# ipro6s register map
Vendor: intelpro; Series: IPRO6S
CPU: ipro6s, little endian
Registers are 32-bit, read-write, reset 0x0 unless marked. A register's access mark holds for its fields unless they carry their own. Offsets are from the block's base; [hi:lo] are bit positions; lines under a group give offsets from that group; {n}, {i} and the like mark numbered series; 'fields as' and 'values as' point back to an identical list.

## GLB
Base 0x30000000
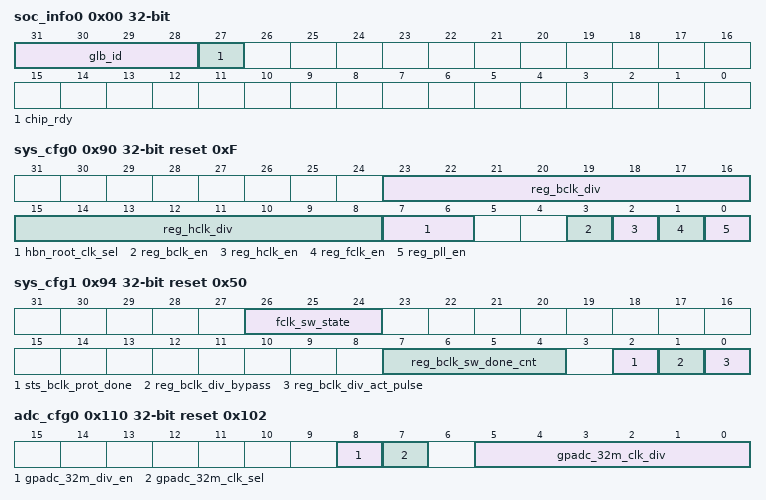
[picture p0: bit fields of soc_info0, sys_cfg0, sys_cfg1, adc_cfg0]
0x00 soc_info0 reset not defined
  [31:28] glb_id ro, [27] chip_rdy ro
0x50 core_cfg16 reset not defined
  [31:0] np_int_sta0 ro — NP interrupt status [31:0]
0x54 core_cfg17 reset not defined
  [31:0] np_int_sta1 ro — NP interrupt status [63:32]
0x58 core_cfg18
  [31:0] np_int_mask0
0x5C core_cfg19
  [31:0] np_int_mask1
0x60 core_cfg20
  [31:0] np_int_clr0 wo
0x64 core_cfg21
  [31:0] np_int_clr1 wo
0x90 sys_cfg0 reset 0xF (reset mask 0xFFFF0F)
  [23:16] reg_bclk_div — bclk divide from hclk
  [15:8] reg_hclk_div — hclk divide from root clock (clock source selected by hbn_root_clk_sel)
  [7:6] hbn_root_clk_sel ro — root clock selection from HBN (0: RC32M 1: XTAL 2/3: PLL others)
  [3] reg_bclk_en — bclk force on
  [2] reg_hclk_en — hclk force on
  [1] reg_fclk_en — fclk force on
  [0] reg_pll_en — pll clock enable for fclk
0x94 sys_cfg1 reset 0x50 (reset mask 0xF3)
  [26:24] fclk_sw_state ro
  [7:4] reg_bclk_sw_done_cnt — BCLK division protection done counter
  [2] sts_bclk_prot_done ro — clk protection done
  [1] reg_bclk_div_bypass — BCLK division protection bypass
  [0] reg_bclk_div_act_pulse wo — BCLK division protection activation
0xA0 bus_cfg0 reset 0xFFFFFFFF
  [31:0] rg_apb_pck_force — APB clock force on
0xF0 rtc_cfg0 reset not defined
0x110 adc_cfg0 reset 0x102
  [8] gpadc_32m_div_en — GPADC 32M Clock Dvider Enable
  [7] gpadc_32m_clk_sel — GPADC Clock Source Select. 0: audio_pll_clk, 1: xclk
  [5:0] gpadc_32m_clk_div — GPADC 32M Clock Divider (audio_pll_clk)/(N+1) , default : audio_pll_clk/3
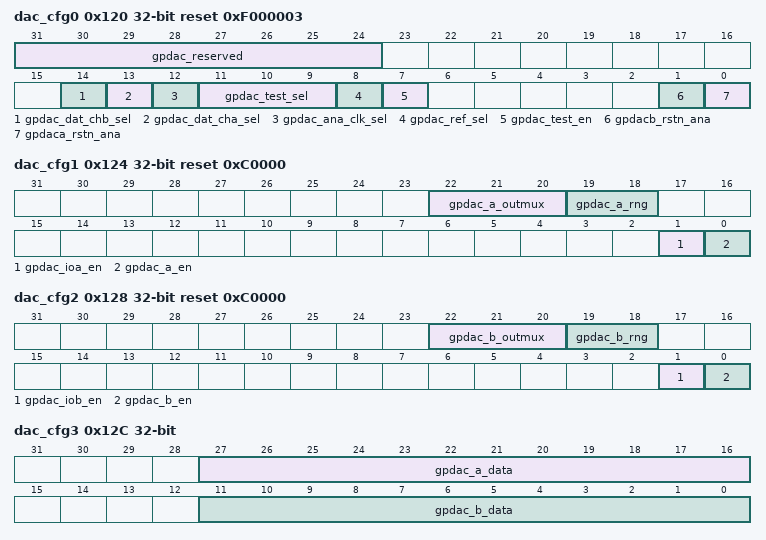
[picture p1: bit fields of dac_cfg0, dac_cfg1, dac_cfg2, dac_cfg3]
0x120 dac_cfg0 reset 0xF000003
  [31:24] gpdac_reserved
  [14] gpdac_dat_chb_sel — 0:data from gpip, 1:data from audio pwm
  [13] gpdac_dat_cha_sel — 0:data from gpip, 1:data from audio pwm
  [12] gpdac_ana_clk_sel — 0:clock from gpip, 1:clock from audio pwm
  [11:9] gpdac_test_sel — select test point 0~7
  [8] gpdac_ref_sel — Reference select 1'h0 Internal reference 1'h1 External reference
  [7] gpdac_test_en — Test enable 1'h0 analog test disabled (ATEST is set in Hi-Z state) 1'h1 analog test point enabled to ATEST
  [1] gpdacb_rstn_ana — Soft reset for DAC channel B, active low
  [0] gpdaca_rstn_ana — Soft reset for DAC channel A, active low
0x124 dac_cfg1 reset 0xC0000
  [22:20] gpdac_a_outmux
  [19:18] gpdac_a_rng — Output voltage range control with internal/external reference
  [1] gpdac_ioa_en — Channel A conversion output to pad enable 1'h0 Disable channel A conversion result to GPIO 1'h1 Enable channel A conversion result to GPIO
  [0] gpdac_a_en — Channel A enable/disable signal 1'h0 Disable channel A conversion. 1'h1 Enable channel A conversion
0x128 dac_cfg2 reset 0xC0000
  [22:20] gpdac_b_outmux
  [19:18] gpdac_b_rng
  [1] gpdac_iob_en — channel B conversion output to pad enable 1'h0 Disable channel B conversion result to GPIO 1'h1 Enable channel B conversion result to GPIO
  [0] gpdac_b_en — channel B enable/disable signal 1'h0 Disable channel B conversion. 1'h1 Enable channel B conversion
0x12C dac_cfg3
  [27:16] gpdac_a_data — Channel A Data input
  [11:0] gpdac_b_data — Channel B Data input
0x130 dma_cfg0 reset 0xFF000000
  [31:24] dma_clk_en — DMA Channel Clock Enable
0x134 dma_cfg1 reset not defined
0x138 dma_cfg2 reset not defined
0x140 ir_cfg0 reset not defined
0x144 ir_cfg1
  [11:8] ir_rx_gpio_sel — 0 : disable ir_rx select gpio 1~15 :select gpio 9 ~ 23 as ir_rx (GPIO need to set as SWGPIO mode)
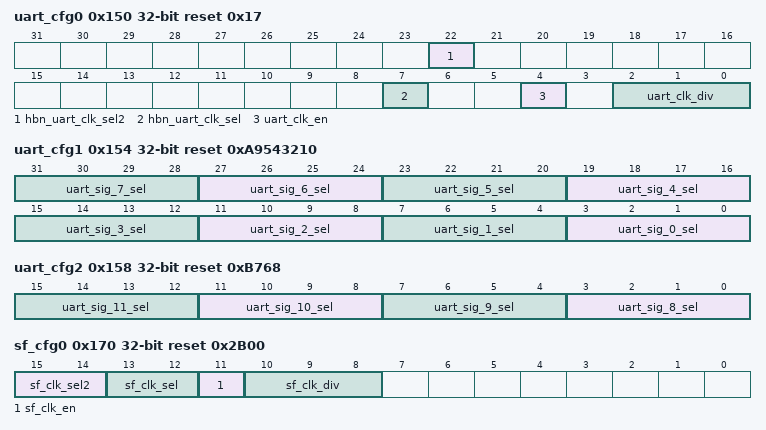
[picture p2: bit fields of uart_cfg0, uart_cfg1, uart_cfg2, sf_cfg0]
0x150 uart_cfg0 reset 0x17 (reset mask 0x17)
  [22] hbn_uart_clk_sel2 ro — UART clock selection2 from HBN (0 : result of hbn_uart_clk_sel (bclk or MUX 160MHz), 1: XCLK (XTAL or RC32M))
  [7] hbn_uart_clk_sel ro — UART clock selection from HBN (0:bclk 1:muxpll_160m_clk)
  [4] uart_clk_en — UART Clock Enable
  [2:0] uart_clk_div — UART Clock Divider (root clock or 160M)/(N+1) (clock source selected by hbn_uart_clk_sel)
0x154 uart_cfg1 reset 0xA9543210
  [4n+3:4n] uart_sig_{n}_sel (n=0..7) — UART Signal{n} Select : 0 : UART0_RTS 1 : UART0_CTS 2 : UART0_TXD 3 : UART0_RXD 4 : UART1_RTS 5 : UART1_CTS 6 : UART1_TXD 7 : UART1_RXD 8 : ~CAN_TXD 9 : x 10 : CAN_TXD 11 : CAN_RXD
0x158 uart_cfg2 reset 0xB768
  [4n-29:4n-32] uart_sig_{n}_sel (n=8..11) — UART Signal{n} Select
0x170 sf_cfg0 reset 0x2B00
  [15:14] sf_clk_sel2 — For sf_clk_sel=0 0/2: wifipll 120MHz 1: XTAL 2: aupll_div5 (98.3 or 90.3MHz) (for De-Spur)
  [13:12] sf_clk_sel — Flash Clock Select 0: clock from sf_clk_sel2 1: clock from muxpll_80m_clk (see 0x20000254 description) 2: bclk 3: wifipll 96MHz
  [11] sf_clk_en — Flash Clock Enable
  [10:8] sf_clk_div — Flash Clock Divider (Selected Flash Clock)/(N+1)
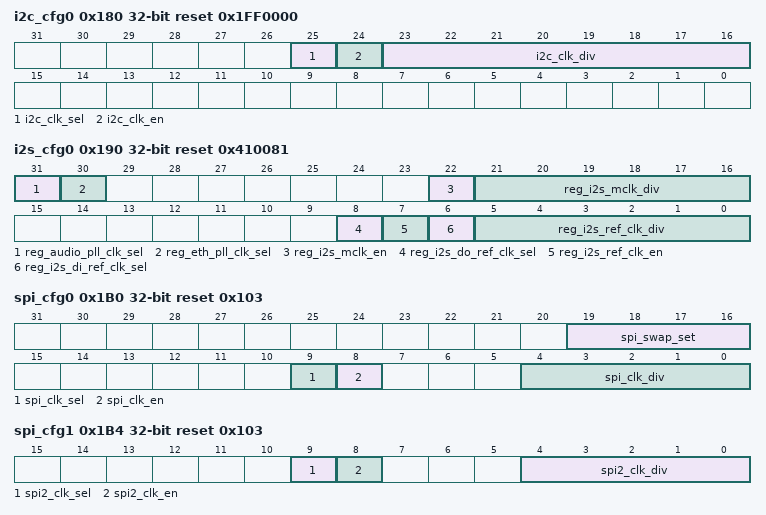
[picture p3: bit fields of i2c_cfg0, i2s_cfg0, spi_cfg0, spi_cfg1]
0x180 i2c_cfg0 reset 0x1FF0000
  [25] i2c_clk_sel — 0 : Bus Clcok to I2C Clock Divider 1 : XCLK clock to I2C Clock Divider
  [24] i2c_clk_en — I2C Master Clock Out Enable
  [23:16] i2c_clk_div — I2C Master Clock Out Divider (Freq_of_BCLK/(N+1))
0x190 i2s_cfg0 reset 0x410081
  [31] reg_audio_pll_clk_sel — 1:sscdiv_clk_out 0:wifipll_postdiv_outclk
  [30] reg_eth_pll_clk_sel — 1:sscdiv_clk_out 0:wifipll_postdiv_outclk
  [22] reg_i2s_mclk_en — Audio I2S Clock Enable
  [21:16] reg_i2s_mclk_div — Audio I2S Clock Divider (AUD_CLK/(N+1)), default AUD_CLK/2
  [8] reg_i2s_do_ref_clk_sel — Audio I2S Clock Output Enable 1 (1: Select i2s_ref_clk output, 0 : Select i2s_do output)
  [7] reg_i2s_ref_clk_en — Audio I2S Clock Enable
  [6] reg_i2s_di_ref_clk_sel — Audio I2S Clock Output Enable 0 (1: Select i2s_ref_clk output, 0: Select i2s_di input)
  [5:0] reg_i2s_ref_clk_div — Audio I2S Clock Divider (AUD_CLK/(N+1)), default AUD_CLK/2
0x1B0 spi_cfg0 reset 0x103
  [19:16] spi_swap_set — [0] SWAP UART GPIO SET0 (GPIO0~GPIO11) (1: spi_sig[0:11] -> spi_sig[6:11], spi_sig[0:5]) [1] SWAP UART GPIO SET0 (GPIO12~GPIO23) (1: spi_sig[0:11] -> spi_sig[6:11], spi_sig[0:5]) [2] SWAP UART GPIO SET0 (GPIO24~GPIO35) (1: spi_sig[0:11] -> spi_sig[6:11], spi_sig[0:5]) [3] SWAP UART GPIO SET0 (GPIO36~GPIO45) (1: spi_sig[0:11] -> spi_sig[6:11], spi_sig[0:5])
  [9] spi_clk_sel — 0 : MUXPLL_160M Hz to SPI Clock Divider (see 0x254h reg_top_muxpll_160m_sel) 1: XCLK (XTAL or RC32M) to SPI Clock Divider
  [8] spi_clk_en — SPI Clock Enable (Default : Enable)
  [4:0] spi_clk_div — SPI Clock Divider (BUS_CLK/(N+1)), default BUS_CLK/4
0x1B4 spi_cfg1 reset 0x103
  [9] spi2_clk_sel — 0 : MUXPLL_160M Hz to SPI Clock Divider (see 0x254h reg_top_muxpll_160m_sel) 1: XCLK (XTAL or RC32M) to SPI Clock Divider
  [8] spi2_clk_en — SPI Clock Enable (Default : Enable)
  [4:0] spi2_clk_div — SPI Clock Divider (BUS_CLK/(N+1)), default BUS_CLK/4
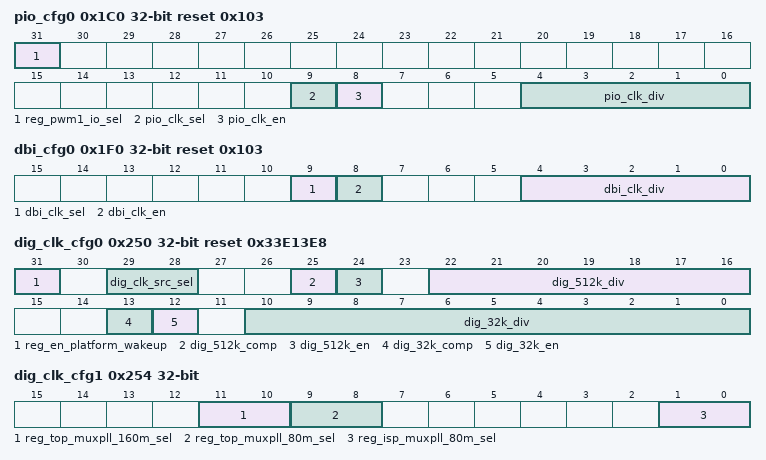
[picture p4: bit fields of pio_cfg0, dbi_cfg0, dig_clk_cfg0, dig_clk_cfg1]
0x1C0 pio_cfg0 reset 0x103
  [31] reg_pwm1_io_sel
  [9] pio_clk_sel — 0 : MUXPLL_160M Hz to PIO Clock Divider (see 0x254h reg_top_muxpll_160m_sel) 1: XCLK (XTAL or RC32M) to PIO Clock Divider
  [8] pio_clk_en — PIO Clock Enable (Default : Enable)
  [4:0] pio_clk_div — PIO Clock Divider (BUS_CLK/(N+1)), default BUS_CLK/4
0x1D0 pwm_cfg0 reset not defined
0x1E0 pdm_cfg0
  [0] reg_pdm_io_sel — 0 : select audio_top PDM, 1: select aupdm_top PDM
0x1F0 dbi_cfg0 reset 0x103
  [9] dbi_clk_sel — 0 : MUXPLL_160M Hz to DBI Clock Divider (see 0x254h reg_top_muxpll_160m_sel) 1: XCLK (XTAL or RC32M) to DBI Clock Divider
  [8] dbi_clk_en — DBI Clock Enable (Default : Enable)
  [4:0] dbi_clk_div — DBI Clock Divider (BUS_CLK/(N+1)), default BUS_CLK/4
0x250 dig_clk_cfg0 reset 0x33E13E8
  [31] reg_en_platform_wakeup — If setting to 1, the platform wakeup will becomes one of pds_wakeup source
  [29:28] dig_clk_src_sel — 0:WIFIPLL 32MHz 1:xclk 2:Audio PLL
  [25] dig_512k_comp — Compensation => Duty of dig_512k_out = N : N+1
  [24] dig_512k_en — Enable dig_512k_out
  [22:16] dig_512k_div — (PLL 32MHz or xclk) / dig_512k_div Ex: Set 46 for 24MHz ; Set 62 for 32MHz ; Set 75 for 38.4MHz ; Set 78 for 40MHz
  [13] dig_32k_comp — Compensation => Duty of dig_32k_out = dig_32k_div : (dig_32k_div+1)
  [12] dig_32k_en — Enable dig_32k_out
  [10:0] dig_32k_div — (PLL 32MHz or xclk) / dig_32k_div Ex: Set 750 for 24MHz ; Set 1000 for 32MHz ; Set 1200 for 38.4MHz ; Set 1250 for 40MHz
0x254 dig_clk_cfg1
  [11:10] reg_top_muxpll_160m_sel — muxpll_160m_clk select from (see 0x2000058C) 0: wifipll_160m_clk 1: aupll_div3_clk 2: top_aupll_div2_clk 3: aupll_div2p5_clk
  [9:8] reg_top_muxpll_80m_sel — muxpll_80m_clk select from (see 0x2000058C) 0: wifipll_80m_clk 1: top_aupll_div5_clk 2/3: top_aupll_div6_clk
  [1:0] reg_isp_muxpll_80m_sel — isp_muxpll_80m_clk select from (see 0x2000058C) 0: wifipll_80m_clk 1: aupll_div5_clk 2/3: aupll_div6_clk
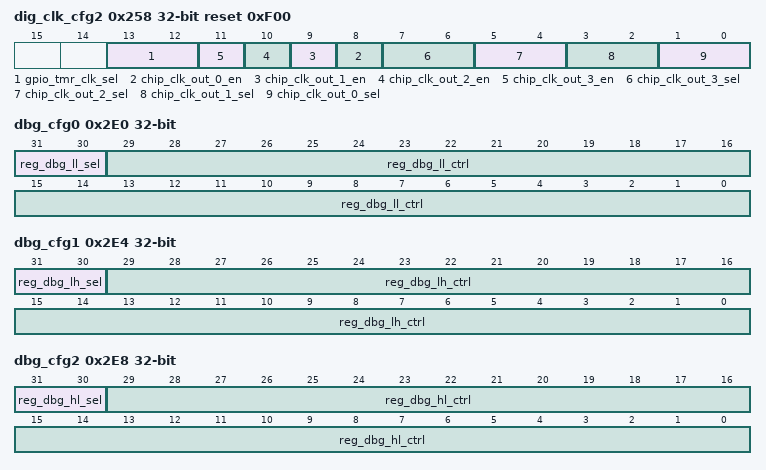
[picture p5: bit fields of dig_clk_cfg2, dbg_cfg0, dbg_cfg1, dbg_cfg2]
0x258 dig_clk_cfg2 reset 0xF00
  [13:12] gpio_tmr_clk_sel — select GPIO Clock Input From GPIO Function 31: 0: chip_clk_inout[0] 1: chip_clk_inout[1] 2: chip_clk_inout[2] 3: chip_clk_inout[3]
  [n+8] chip_clk_out_{n}_en (n=0..3) — 1: chip_clk_out_{n} output enable, 0 : chip_clk_out_{n} output disable (clock input mode)
  [7:6] chip_clk_out_3_sel — chip_clk_out_3 selection (0: cam_reg_clk, 1: i2s_ref_clk out, 2: i2s_mclk, 3: pll_48m_clk)
  [5:4] chip_clk_out_2_sel — chip_clk_out_2 selection (0: cam_reg_clk, 1: i2s_ref_clk out, 2: ana_xtal_clk, 3: pll_32m_clk)
  [3:2] chip_clk_out_1_sel — chip_clk_out_1 selection (0: cam_reg_clk, 1: i2s_ref_clk out, 2: i2s_mclk, 3: 0)
  [1:0] chip_clk_out_0_sel — chip_clk_out_0 selection (0: cam_reg_clk, 1: i2s_ref_clk out, 2: i2s_mclk, 3: 0)
0x25C dig_clk_cfg3 reset not defined
0x260 rf_cfg0 reset not defined
0x2E0 dbg_cfg0
  [31:30] reg_dbg_ll_sel — [1:0] Debug Selection : 00 : select [7:0] of debug set signal 01 : select [15:8] of debug set signal 10 : select [23:16] of debug set signal 11 : select [31:24] of debug set signal
  [29:0] reg_dbg_ll_ctrl — [31:2] Debug Set : 1~30 Debug Signal Set selection, and Only one bit can be asserted for selection
0x2E4 dbg_cfg1
  [31:30] reg_dbg_lh_sel — [1:0] Debug Selection : 00 : select [7:0] of debug set signal 01 : select [15:8] of debug set signal 10 : select [23:16] of debug set signal 11 : select [31:24] of debug set signal
  [29:0] reg_dbg_lh_ctrl — [31:2] Debug Set : 1~30 Debug Signal Set selection, and Only one bit can be asserted for selection
0x2E8 dbg_cfg2
  [31:30] reg_dbg_hl_sel — [1:0] Debug Selection : 00 : select [7:0] of debug set signal 01 : select [15:8] of debug set signal 10 : select [23:16] of debug set signal 11 : select [31:24] of debug set signal
  [29:0] reg_dbg_hl_ctrl — [31:2] Debug Set : 1~30 Debug Signal Set selection, and Only one bit can be asserted for selection
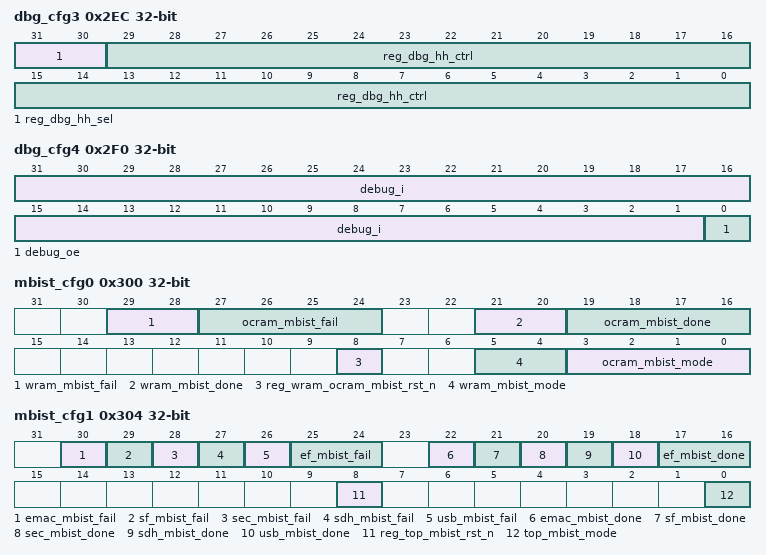
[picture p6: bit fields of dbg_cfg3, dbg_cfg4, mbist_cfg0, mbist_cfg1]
0x2EC dbg_cfg3
  [31:30] reg_dbg_hh_sel — [1:0] Debug Selection : 00 : select [7:0] of debug set signal 01 : select [15:8] of debug set signal 10 : select [23:16] of debug set signal 11 : select [31:24] of debug set signal
  [29:0] reg_dbg_hh_ctrl — [31:2] Debug Set : 1~30 Debug Signal Set selection, and Only one bit can be asserted for selection
0x2F0 dbg_cfg4 (reset mask 0x1)
  [31:1] debug_i ro, [0] debug_oe
0x300 mbist_cfg0 (reset mask 0x13F)
  [29:28] wram_mbist_fail ro, [27:24] ocram_mbist_fail ro, [21:20] wram_mbist_done ro, [19:16] ocram_mbist_done ro, [8] reg_wram_ocram_mbist_rst_n, [5:4] wram_mbist_mode, [3:0] ocram_mbist_mode
0x304 mbist_cfg1 (reset mask 0x101)
  [30] emac_mbist_fail ro, [29] sf_mbist_fail ro, [28] sec_mbist_fail ro, [27] sdh_mbist_fail ro, [26] usb_mbist_fail ro, [25:24] ef_mbist_fail ro, [22] emac_mbist_done ro, [21] sf_mbist_done ro, [20] sec_mbist_done ro, [19] sdh_mbist_done ro, [18] usb_mbist_done ro, [17:16] ef_mbist_done ro, [8] reg_top_mbist_rst_n, [0] top_mbist_mode
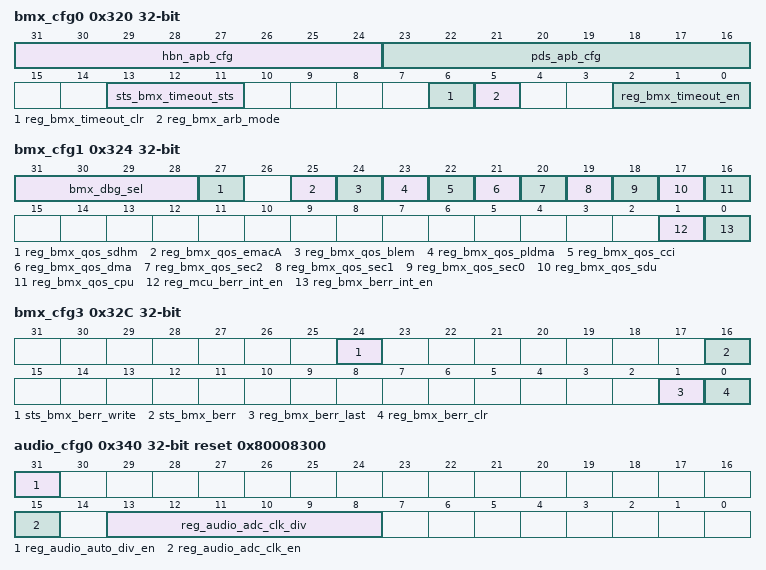
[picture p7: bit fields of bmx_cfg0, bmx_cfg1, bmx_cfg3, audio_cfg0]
0x320 bmx_cfg0 (reset mask 0xFFFF0067)
  [31:24] hbn_apb_cfg — HW reserved. [7] hbn_hold_en [6:4] hbn_hold_cycle [3] hbn_setup_en [2:0] hbn_setup_cycle
  [23:16] pds_apb_cfg
  [13:11] sts_bmx_timeout_sts ro — Bus timeout error status
  [6] reg_bmx_timeout_clr — Bus timeout error clear
  [5] reg_bmx_arb_mode — Bus arbiter: 1:fix, 0:round-robin
  [2:0] reg_bmx_timeout_en — Bus timeout enable: detect slave no reaponse in 1024 cycles
0x324 bmx_cfg1
  [31:28] bmx_dbg_sel — For debug
  [27] reg_bmx_qos_sdhm — SDHM on bmx qos
  [25] reg_bmx_qos_emacA — EMACA on bmx qos
  [24] reg_bmx_qos_blem — BLEM on bmx qos
  [23] reg_bmx_qos_pldma — PLDMA on bmx qos
  [22] reg_bmx_qos_cci — CCI on bmx qos
  [21] reg_bmx_qos_dma — DMA on bmx qos
  [20] reg_bmx_qos_sec2 — GMAC0 on bmx qos
  [19] reg_bmx_qos_sec1 — AES0 on bmx qos
  [18] reg_bmx_qos_sec0 — SHA0 on bmx qos
  [17] reg_bmx_qos_sdu — SDU on bmx qos
  [16] reg_bmx_qos_cpu — CPU on bmx qos
  [1] reg_mcu_berr_int_en — Bus addr decode interrupt enable
  [0] reg_bmx_berr_int_en — Bus addr decode interrupt enable
0x328 bmx_cfg2 reset 0x3FF
  [9:0] reg_bmx_berr_en — bus decode error source enable [ 0] - mcu decode [ 1] - Connection group decode (EMAC / SDH) [ 2] - Security group decode [ 3] - DMA group decode [ 4] - Pico A decode [ 5] - Pico B decode [ 6] - Peripheral decode [ 7] - MM/EXT decode [ 8] - DMA slave security [ 9] - Power slave security [10] - WRAM securituy [11] - DMA2 slave security [12] - WL2MM salve security [13] - OCRAM security
0x32C bmx_cfg3 (reset mask 0x3)
  [24] sts_bmx_berr_write ro — Bus addr decode error write index
  [16] sts_bmx_berr ro — Bus addr decode error
  [1] reg_bmx_berr_last — Bus addr error monitor latch mode 1'b0 - Latch first error 1'b1 - Latch last error
  [0] reg_bmx_berr_clr — Bus addr decode error clear
0x340 audio_cfg0 reset 0x80008300
  [31] reg_audio_auto_div_en — Audio auto clock div enable
  [15] reg_audio_adc_clk_en — Audio ADC Clock Enable
  [13:8] reg_audio_adc_clk_div — Audio ADC Clock Divider (AUD_CLK/(N+1)), default AUD_CLK/2
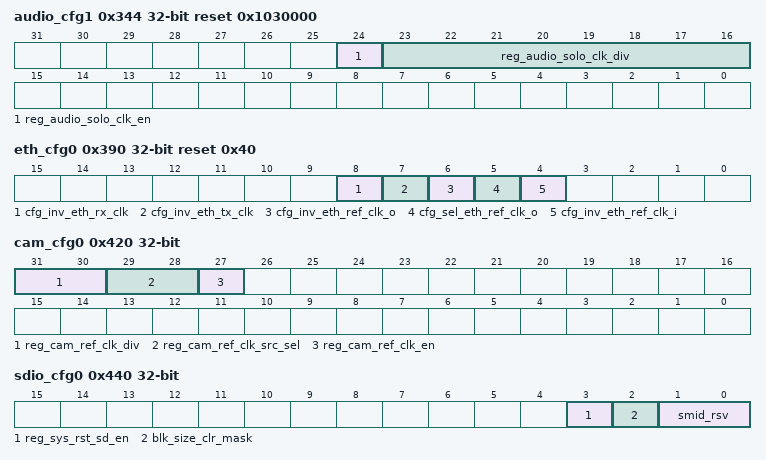
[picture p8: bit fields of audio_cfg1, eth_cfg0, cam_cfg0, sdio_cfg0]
0x344 audio_cfg1 reset 0x1030000
  [24] reg_audio_solo_clk_en — SOLO Clock Enable
  [23:16] reg_audio_solo_clk_div — SOLO Clock Divider (AUD_CLK/(N+1)),
0x390 eth_cfg0 reset 0x40
  [8] cfg_inv_eth_rx_clk — (For RMII MAC1) Invert clock to our RMII MAC1 RX
  [7] cfg_inv_eth_tx_clk — (For RMII MAC1) Invert clock to our RMII MAC1 TX
  [6] cfg_inv_eth_ref_clk_o — (For RMII MAC1) if [5] = 1, set this bit to 1 will invert the clock to RMII PHY1
  [5] cfg_sel_eth_ref_clk_o — (For RMII MAC1) 0 : select outside 50MHz RMII ref clock, 1: select inside 50MHz RMII ref clock (MIPIPLL)
  [4] cfg_inv_eth_ref_clk_i — (For RMII MAC1) Invert clock to RMII REF_CLK
0x420 cam_cfg0
  [31:30] reg_cam_ref_clk_div — CAM Reference Clock Divider ref_clk_src/(N+1)
  [29:28] reg_cam_ref_clk_src_sel — CAM Reference Clock Source Selection (0:xclk; 1: 96MHz WIFI PLL Clock, 2/3: 100MHz cpupll Clock)
  [27] reg_cam_ref_clk_en — CAM Reference Clock Out Enable
0x430 sdh_cfg0 reset not defined
0x440 sdio_cfg0
  [3] reg_sys_rst_sd_en — Enable Host config 0x6[3] abort to reset System
  [2] blk_size_clr_mask — HW reserved
  [1:0] smid_rsv — HW reserved
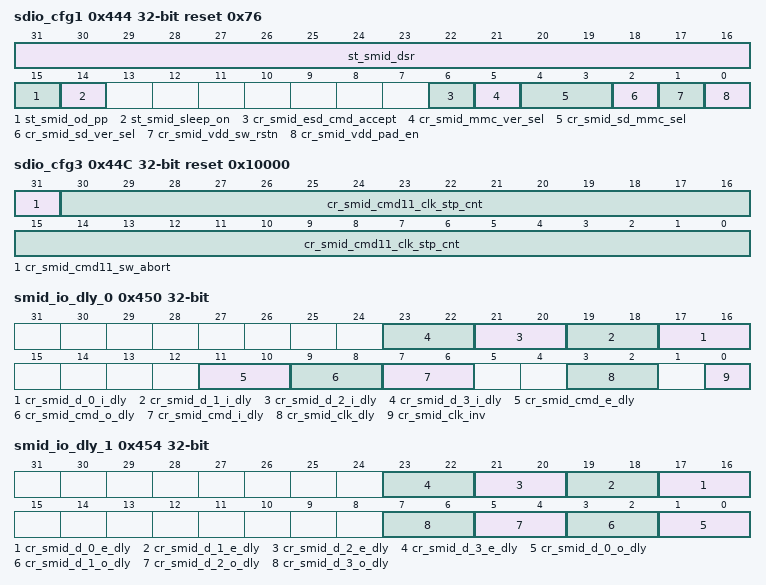
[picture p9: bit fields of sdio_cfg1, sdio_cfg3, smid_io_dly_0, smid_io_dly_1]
0x444 sdio_cfg1 reset 0x76 (reset mask 0x7F)
  [31:16] st_smid_dsr ro — DSR status
  [15] st_smid_od_pp ro — Used only in MMC mode. This signal is used to control the Push pull resitor on the MMC IO bus.
  [14] st_smid_sleep_on ro — Device controller receives read/write command, which requires system bus to do data transaction with System Memory. This signal can be used to shutdown the system clock for Low Power Consumption.
  [6] cr_smid_esd_cmd_accept — 0-Do not accept eSD commands, 1-Accept eSD commands
  [5] cr_smid_mmc_ver_sel — 0-MMC4.2, 1-eMMC4.4
  [4:3] cr_smid_sd_mmc_sel — 00-SD/eSD, 01-MMC, 10-SDIO, 11-SD/SDIO combo
  [2] cr_smid_sd_ver_sel — 0-SD2.0, 1-SD3.0
  [1] cr_smid_vdd_sw_rstn — SW control signal when SMID_VDD pin is invalid
  [0] cr_smid_vdd_pad_en — SMID_VDD pad connection enable
0x448 sdio_cfg2 reset 0x21FF8000
  [31:0] cr_smid_ocr — Card OCR - Operational Condition Register
0x44C sdio_cfg3 reset 0x10000
  [31] cr_smid_cmd11_sw_abort wo — CMD11 SW abort
  [30:0] cr_smid_cmd11_clk_stp_cnt — CMD11 clock stop count
0x450 smid_io_dly_0
  [2n+17:2n+16] cr_smid_d_{n}_i_dly (n=0..3) — SMID_DATA{n}_I delay select
  [11:10] cr_smid_cmd_e_dly — SMID_CMD_OE delay select
  [9:8] cr_smid_cmd_o_dly — SMID_CMD_O delay select
  [7:6] cr_smid_cmd_i_dly — SMID_CMD_I delay select
  [3:2] cr_smid_clk_dly — SMID_CLK delay select
  [0] cr_smid_clk_inv — SMID_CLK inverse
0x454 smid_io_dly_1
  [2n+17:2n+16] cr_smid_d_{n}_e_dly (n=0..3) — SMID_DATA{n}_OE delay select
  [2n+1:2n] cr_smid_d_{n}_o_dly (n=0..3) — SMID_DATA{n}_O delay select
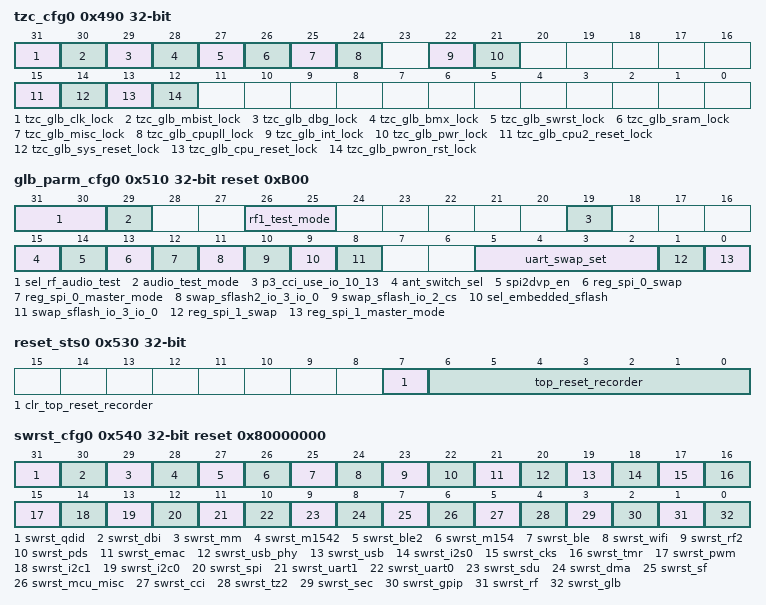
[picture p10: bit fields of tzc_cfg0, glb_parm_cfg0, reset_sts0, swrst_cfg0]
0x490 tzc_cfg0 reset not defined
  [31] tzc_glb_clk_lock ro
  [30] tzc_glb_mbist_lock ro
  [29] tzc_glb_dbg_lock ro
  [28] tzc_glb_bmx_lock ro
  [27] tzc_glb_swrst_lock ro
  [26] tzc_glb_sram_lock ro
  [25] tzc_glb_misc_lock ro
  [24] tzc_glb_cpupll_lock ro — (HW Use) Same as tzc_glb_clk_lock, and used for At-Speed Scan
  [22] tzc_glb_int_lock ro
  [21] tzc_glb_pwr_lock ro
  [15] tzc_glb_cpu2_reset_lock ro
  [14] tzc_glb_sys_reset_lock ro
  [13] tzc_glb_cpu_reset_lock ro
  [12] tzc_glb_pwron_rst_lock ro
0x510 glb_parm_cfg0 reset 0xB00
  [31:30] sel_rf_audio_test — (Used with Bit[17]/[18]/[20]/[21] 00: No GPIO Scenario on RF1/RF2/Audio ADC/DAC Test 01: GPIO Scenario Bit [17]/[18]/[20]/[21] used for RF1 10: GPIO Scenario Bit [17]/[18]/[20]/[21] used for RF2 11: GPIO Scenario Bit [17]/[18]/[20]/[21] used for Audio
  [29] audio_test_mode — 0 : select audio_test_in, 1: select audio_test_out
  [26:25] rf1_test_mode — 00: no rf_test signal mux to rf_test_x 01: select rf1 adc signal mux to rf_test_x 10/11:select rf1 dac signal mux to rf_test_x
  [19] p3_cci_use_io_10_13 — GPIO Scenario, set this bit will force GPIO10~13 to CCI Function
  [15] ant_switch_sel — 0 : Select btdm antenna switch output, 1: Select ble2 antenna switch output
  [14] spi2dvp_en — SPI2DVP function enable
  [13] reg_spi_0_swap — 1: SWAP SPI0 MOSI with MISO ; 0 No SWAP
  [12] reg_spi_0_master_mode — 1 : SPI_0 Pad Act as Master, 0: SPI_0 Pad Act as Slave
  [11] swap_sflash2_io_3_io_0 — 1 : SWAP SFLASH2 IO 3 with IO 0 : No SWAP SFLASH2 IO 3 With IO0
  [10] swap_sflash_io_2_cs — 0 : Origianl IO2 and CS 1 : SWAP IO2 and CS
  [9] sel_embedded_sflash — 0 : Select External Sflash 1: Select Embedded Sflash (Default)
  [8] swap_sflash_io_3_io_0 — 1 : SWAP SFLASH IO 3 with IO 0 : No SWAP SFLASH IO 3 With IO0
  [5:2] uart_swap_set — [0] SWAP UART GPIO SET0 (GPIO0~GPIO11) (1: uart_sig[0:11] -> uart_sig[6:11], uart_sig[0:5] [0] SWAP UART GPIO SET0 (GPIO0~GPIO11) (1: uart_sig[0:11] -> uart_sig[6:11], uart_sig[0:5] [0] SWAP UART GPIO SET0 (GPIO0~GPIO11) (1: uart_sig[0:11] -> uart_sig[6:11], uart_sig[0:5]
  [1] reg_spi_1_swap — 1: SWAP SPI_1 MOSI with MISO ; 0 No SWAP
  [0] reg_spi_1_master_mode — 1 : SPI_1 Pad Act as Master, 0: SPI_1 Pad Act as Slave
0x520 debug_cfg0 reset not defined
0x524 debug_cfg1
  [20] debug_ndreset_gate — Gating CPU debug reset
0x530 reset_sts0 (reset mask 0x80)
  [7] clr_top_reset_recorder — 1: clear top_reset_recorder, 0 : keep record reset reason
  [6:0] top_reset_recorder ro — [0]:reset_recorder_ana_powb [1]:reset_recorder_ext_rst_n [2]:reset_recorder_pds_reset [3]:reset_recorder_wdt_rst_n [4]:reset_recorder_cpu_porst_n [5]:reset_recorder_sys_reset_n [6]:reset_recorder_cpu_sys_rstreq_n
0x540 swrst_cfg0 reset 0x80000000
  [31] swrst_qdid, [30] swrst_dbi, [29] swrst_mm, [28] swrst_m1542, [27] swrst_ble2, [26] swrst_m154, [25] swrst_ble, [24] swrst_wifi, [23] swrst_rf2, [22] swrst_pds, [21] swrst_emac, [20] swrst_usb_phy, [19] swrst_usb, [18] swrst_i2s0, [17] swrst_cks, [16] swrst_tmr, [15] swrst_pwm, [14] swrst_i2c1, [13] swrst_i2c0, [12] swrst_spi, [11] swrst_uart1, [10] swrst_uart0, [9] swrst_sdu, [8] swrst_dma, [7] swrst_sf, [6] swrst_mcu_misc, [5] swrst_cci, [4] swrst_tz2, [3] swrst_sec, [2] swrst_gpip, [1] swrst_rf, [0] swrst_glb
0x544 swrst_cfg1 — swrst_s1
  [0] swrst_spi2
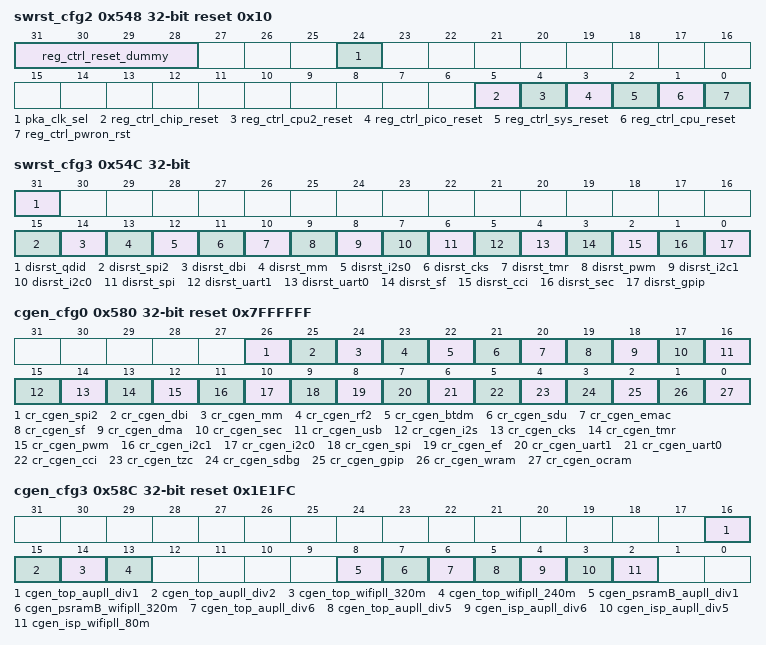
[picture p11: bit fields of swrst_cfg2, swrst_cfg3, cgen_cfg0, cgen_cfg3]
0x548 swrst_cfg2 reset 0x10
  [31:28] reg_ctrl_reset_dummy
  [24] pka_clk_sel — 0:bclk, 1: muxpll_160m_clk
  [5] reg_ctrl_chip_reset
  [4] reg_ctrl_cpu2_reset
  [3] reg_ctrl_pico_reset
  [2] reg_ctrl_sys_reset
  [1] reg_ctrl_cpu_reset
  [0] reg_ctrl_pwron_rst
0x54C swrst_cfg3
  [31] disrst_qdid, [15] disrst_spi2, [14] disrst_dbi, [13] disrst_mm, [12] disrst_i2s0, [11] disrst_cks, [10] disrst_tmr, [9] disrst_pwm, [8] disrst_i2c1, [7] disrst_i2c0, [6] disrst_spi, [5] disrst_uart1, [4] disrst_uart0, [3] disrst_sf, [2] disrst_cci, [1] disrst_sec, [0] disrst_gpip
0x580 cgen_cfg0 reset 0x7FFFFFF — cgen_m
  [26] cr_cgen_spi2 — CGEN for module Bus Master Clock (BCLK)
  [25] cr_cgen_dbi — CGEN for module Bus Master Clock (BCLK)
  [24] cr_cgen_mm — CGEN for module Bus Master Clock (BCLK)
  [23] cr_cgen_rf2 — CGEN for module Bus Master Clock (BCLK)
  [22] cr_cgen_btdm — CGEN for module Bus Master Clock (BCLK)
  [21] cr_cgen_sdu — CGEN for module Bus Master Clock (BCLK)
  [20] cr_cgen_emac — CGEN for module Bus Master Clock (BCLK)
  [19] cr_cgen_sf — CGEN for module Bus Master Clock (BCLK)
  [18] cr_cgen_dma — CGEN for module Bus Master Clock (BCLK)
  [17] cr_cgen_sec — CGEN for module Bus Master Clock (BCLK)
  [16] cr_cgen_usb — CGEN for module Bus Master Clock (BCLK)
  [15] cr_cgen_i2s — CGEN for module Bus Master Clock (BCLK)
  [14] cr_cgen_cks — CGEN for module Bus Master Clock (BCLK)
  [13] cr_cgen_tmr — CGEN for module Bus Master Clock (BCLK)
  [12] cr_cgen_pwm — CGEN for module Bus Master Clock (BCLK)
  [11] cr_cgen_i2c1 — CGEN for module Bus Master Clock (BCLK)
  [10] cr_cgen_i2c0 — CGEN for module Bus Master Clock (BCLK)
  [9] cr_cgen_spi — CGEN for module Bus Master Clock (BCLK)
  [8] cr_cgen_ef — CGEN for module Bus Master Clock (BCLK)
  [7] cr_cgen_uart1 — CGEN for module Bus Master Clock (BCLK)
  [6] cr_cgen_uart0 — CGEN for module Bus Master Clock (BCLK)
  [5] cr_cgen_cci — CGEN for module Bus Master Clock (BCLK)
  [4] cr_cgen_tzc — CGEN for module Bus Master Clock (BCLK)
  [3] cr_cgen_sdbg — CGEN for module Bus Master Clock (BCLK)
  [2] cr_cgen_gpip — CGEN for module Bus Master Clock (BCLK)
  [1] cr_cgen_wram — CGEN for module Bus Master Clock (BCLK)
  [0] cr_cgen_ocram — CGEN for module Bus Master Clock (BCLK)
0x584 cgen_cfg1 reset not defined — cgen_s1a + cgen_s1
0x588 cgen_cfg2 reset not defined — cgen_s1_ext + cgen_s3
0x58C cgen_cfg3 reset 0x1E1FC
  [16] cgen_top_aupll_div1 — CGEN for AUPLL_DIV1 to TOP
  [15] cgen_top_aupll_div2 — CGEN for AUPLL_DIV2 to TOP
  [14] cgen_top_wifipll_320m — CGEN for WIFIPLL 320MHz to TOP
  [13] cgen_top_wifipll_240m — CGEN for WIFIPLL 240MHz to TOP
  [8] cgen_psramB_aupll_div1 — CGEN for AUPLL_DIV1 to psramB
  [7] cgen_psramB_wifipll_320m — CGEN for WIFIPLL 320MHz to psramB
  [6] cgen_top_aupll_div6 — CGEN for AUPLL DIV6 to TOP
  [5] cgen_top_aupll_div5 — CGEN for AUPLL DIV5 to TOP
  [4] cgen_isp_aupll_div6 — CGEN for AUPLL DIV6 to ISP
  [3] cgen_isp_aupll_div5 — CGEN for AUPLL DIV5 to ISP
  [2] cgen_isp_wifipll_80m — CGEN for WIFIPLL 80M to ISP
{0x5C0+4i} hw_rsv{i} (i=0..2)
0x5CC hw_rsv3 reset 0xFFFFFFFF
0x600 sram_cfg0 reset not defined — reg_sram_ret
0x604 sram_cfg1 reset not defined — reg_sram_slp
0x608 sram_cfg2 reset not defined — reg_sram_parm
0x60C sram_cfg3 reset 0x3
  [3:0] em_sel — 16KB for each bit
0x610 sram_cfg4 reset not defined — reg_sram_parm2
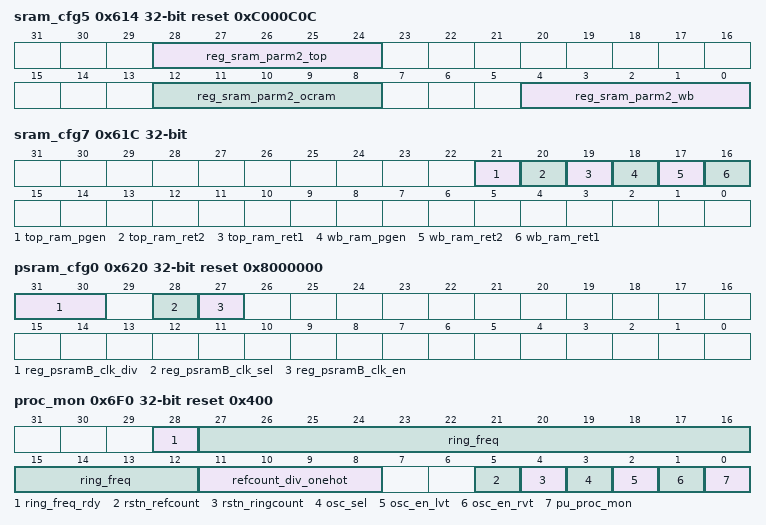
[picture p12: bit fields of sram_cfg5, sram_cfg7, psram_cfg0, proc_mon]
0x614 sram_cfg5 reset 0xC000C0C
  [28:24] reg_sram_parm2_top — [28]=ram_bus[32]=DVSE [27:24]=ram_bus[31:28]=DVS
  [12:8] reg_sram_parm2_ocram — [12]=ram_bus[32]=DVSE [11:8]=ram_bus[31:28]=DVS
  [4:0] reg_sram_parm2_wb — [5]=ram_bus[32]=DVSE [4:0]=ram_bus[31:28]=DVS
0x618 sram_cfg6 reset 0xC2DA000
  [30:12] reg_sram_parm1 — [30:29]=ram_bus[27:26]=WABLM_SRAM [28:26]=ram_bus[25:23]=EMA_SRAM [25:24]=ram_bus[22:21]=WABLM_RF [23:22]=ram_bus[20:19]=RAWLM [21]=ram_bus[18]=WABL [20]=ram_bus[17]=RAWL [19:18]=ram_bus[16:15]=EMAW [17:15]=ram_bus[14:12]=EMA_RF [14:12]=ram_bus[11:9]=EMA_ROM
0x61C sram_cfg7
  [21] top_ram_pgen, [20] top_ram_ret2, [19] top_ram_ret1, [18] wb_ram_pgen, [17] wb_ram_ret2, [16] wb_ram_ret1
0x620 psram_cfg0 reset 0x8000000
  [31:30] reg_psramB_clk_div
  [28] reg_psramB_clk_sel — 0 : emi_wifipll_320m_clk (see 0x2000058C[7]) 1 : emi_aupll_div1_clk (see 0x2000058C[8])
  [27] reg_psramB_clk_en
0x6F0 proc_mon reset 0x400 (reset mask 0xF3F)
  [28] ring_freq_rdy ro
  [27:12] ring_freq ro
  [11:8] refcount_div_onehot
  [5] rstn_refcount
  [4] rstn_ringcount
  [3] osc_sel
  [2] osc_en_lvt
  [1] osc_en_rvt
  [0] pu_proc_mon — power up proc_mon circuit
0x700 dll_cfg0 reset not defined
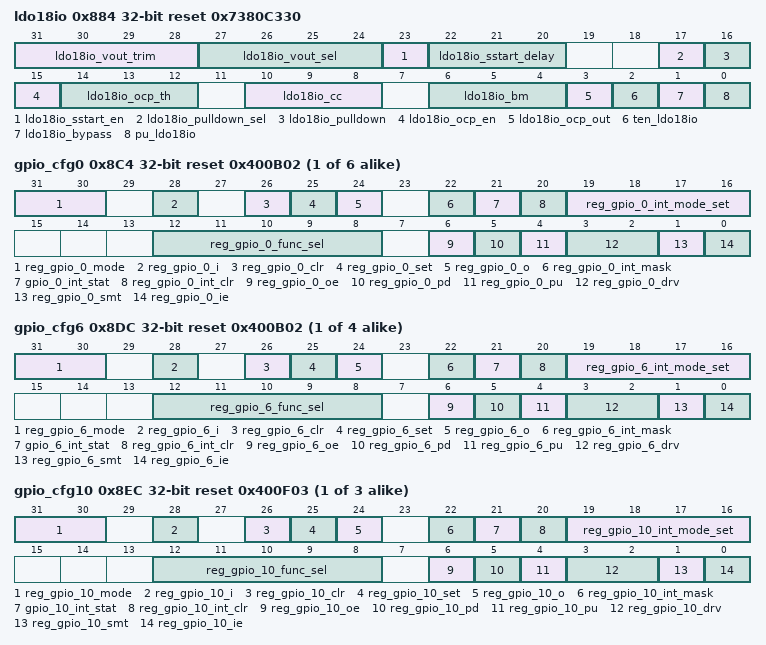
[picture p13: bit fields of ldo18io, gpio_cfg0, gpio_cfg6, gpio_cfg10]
0x884 ldo18io reset 0x7380C330 (reset mask 0xFFF3F777)
  [31:28] ldo18io_vout_trim — output voltage trim 0: 93%, 1: 94%, 7: 100%, 8: 101%, 15: 108%
  [27:24] ldo18io_vout_sel — output voltage selection, 0: 1.65V, 1: 1.70V 2: 1.75V, 3: 1.80V, 4: 1.85V, 5: 1.90V, 6: 1.95V, 7: 2.00V, 8: 2.60V, 9: 2.70V, a: 2.80V, b: 2.90V, c: 2.95V, d: 3.00V, e: 3.05V, f: 3.10V
  [23] ldo18io_sstart_en — soft start circuit enable
  [22:20] ldo18io_sstart_delay — soft start circuit delay time controlling 0: 200us, 3: 500us, 7: 900us
  [17] ldo18io_pulldown_sel — 0: pull down by pu_ldo18io; 1: pull down by ldo18io_pulldown
  [16] ldo18io_pulldown — (worked when ldo18io_pulldown_sel=1) 0: ldo18io output floating, 1: ldo18io output pull down
  [15] ldo18io_ocp_en — Over Current Protect circuit enable
  [14:12] ldo18io_ocp_th — OCP threshold set, 0: 500mA, 1: 500mA, 2: 500mA, 3: 600mA, 4: 800mA, 5: 1000mA, 6: 1200mA, 7: 1200mA
  [10:8] ldo18io_cc — compensation capacitor selection
  [6:4] ldo18io_bm — ldo18io bias mode selection
  [3] ldo18io_ocp_out ro — ldo18io ocp signal
  [2] ten_ldo18io — test mode enable
  [1] ldo18io_bypass — ldo18io work mode selection, 0: LDO mode, 1: bypass mode
  [0] pu_ldo18io — power up ldo18io
0x8A4 gauge reset not defined
{0x8C4+4i} gpio_cfg{i} reset 0x400B02 (reset mask 0xC75F1F7F) (i=0..5)
  [31:30] reg_gpio_{i}_mode — When GPIO Function Selected to SWGPIO 00 (Output Value Mode): GPIO Output by reg_gpio_x_o Value 01 (Set/Celar Mode ) :GPIO Output set by reg_gpio_x_set and clear by reg_gpio_x_clr 10 : SWGPIO Source comes from GPIO DMA (GPIO DMA Mode), GPIO Output value by gpio_dma_o 11: SWGPIO Source comes from GPIO DMA (GPIO DMA Mode), GPIO Outout value by gpio_dma_set/gpio_dma_clr
  [28] reg_gpio_{i}_i ro
  [26] reg_gpio_{i}_clr wo — When SWGPIO @ Set/Clear Mode Set this bit will clear GPIO output value to 0,when set/clr at the same time, only set take effect
  [25] reg_gpio_{i}_set wo — When SWGPIO @ Set/Clear Mode Set this bit will set GPIO output value to 1,when set/clr at the same time, only set take effect
  [24] reg_gpio_{i}_o — When SWGPIO @ Output Value Mode 00 : GPIO Value changes according to this value 01 : GPIO Value Set by this register and clr by clr_reg
  [22] reg_gpio_{i}_int_mask — mask interrupt (1)
  [21] gpio_{i}_int_stat ro — interrupt status
  [20] reg_gpio_{i}_int_clr — clear interrupt
  [19:16] reg_gpio_{i}_int_mode_set — 0000 : sync falling edge trigger 0001 : sync rising edge trigger 0010 : sync low level trigger 0011 : sync high level trigger 01xx : sync rising & falling edge trigger 1000 : async falling edge trigger 1001 : async rising edge trigger 1010 : async low level trigger 1011 : async high level trigger
  [12:8] reg_gpio_{i}_func_sel — GPIO Function Select (Default : SWGPIO)
  [6] reg_gpio_{i}_oe — Register Controlled GPIO Output Enable (Used when GPIO Function select to Register Control GPIO)
  [5] reg_gpio_{i}_pd — GPIO Pull Down Control
  [4] reg_gpio_{i}_pu — GPIO Pull Up Control
  [3:2] reg_gpio_{i}_drv — GPIO Driving Control
  [1] reg_gpio_{i}_smt — GPIO SMT Control
  [0] reg_gpio_{i}_ie — GPIO Input Enable
{0x8C4+4i} gpio_cfg{i} reset 0x400B02 (reset mask 0xC75F1F7F) (i=6..9)
  [31:30] reg_gpio_{i}_mode — When GPIO Function Selected to SWGPIO 00 (Output Value Mode): GPIO Output by reg_gpio_x_o Value 01 (Set/Celar Mode ) :GPIO Output set by reg_gpio_x_set and clear by reg_gpio_x_clr 10 : SWGPIO Source comes from GPIO DMA (GPIO DMA Mode), GPIO Output value by gpio_dma_o 11: SWGPIO Source comes from GPIO DMA (GPIO DMA Mode), GPIO Outout value by gpio_dma_set/gpio_dma_clr
  [28] reg_gpio_{i}_i ro
  [26] reg_gpio_{i}_clr wo — When SWGPIO @ Set/Clear Mode Set this bit will clear GPIO output value to 0,when set/clr at the same time, only set take effect
  [25] reg_gpio_{i}_set wo — When SWGPIO @ Set/Clear Mode Set this bit will set GPIO output value to 1,when set/clr at the same time, only set take effect
  [24] reg_gpio_{i}_o — When SWGPIO @ Output Value Mode 00 : GPIO Value changes according to this value 01 : GPIO Value Set by this register and clr by clr_reg
  [22] reg_gpio_{i}_int_mask — mask interrupt (1)
  [21] gpio_{i}_int_stat ro — interrupt status
  [20] reg_gpio_{i}_int_clr — clear interrupt
  [19:16] reg_gpio_{i}_int_mode_set — 0000 : sync falling edge trigger 0001 : sync rising edge trigger 0010 : sync low level trigger 0011 : sync high level trigger 01xx : sync rising & falling edge trigger 1000 : async falling edge trigger 1001 : async rising edge trigger 1010 : async low level trigger 1011 : async high level trigger
  [12:8] reg_gpio_{i}_func_sel — GPIO Function Select (Default : SW-GPIO)
  [6] reg_gpio_{i}_oe — Register Controlled GPIO Output Enable (Used when GPIO Function select to Register Control GPIO)
  [5] reg_gpio_{i}_pd — GPIO Pull Down Control
  [4] reg_gpio_{i}_pu — GPIO Pull Up Control
  [3:2] reg_gpio_{i}_drv — GPIO Driving Control
  [1] reg_gpio_{i}_smt — GPIO SMT Control
  [0] reg_gpio_{i}_ie — GPIO Input Enable
{0x8C4+4i} gpio_cfg{i} reset 0x400F03 (reset mask 0xC75F1F7F) (i=10..12)
  [31:30] reg_gpio_{i}_mode — When GPIO Function Selected to SWGPIO 00 (Output Value Mode): GPIO Output by reg_gpio_x_o Value 01 (Set/Celar Mode ) :GPIO Output set by reg_gpio_x_set and clear by reg_gpio_x_clr 10 : SWGPIO Source comes from GPIO DMA (GPIO DMA Mode), GPIO Output value by gpio_dma_o 11: SWGPIO Source comes from GPIO DMA (GPIO DMA Mode), GPIO Outout value by gpio_dma_set/gpio_dma_clr
  [28] reg_gpio_{i}_i ro
  [26] reg_gpio_{i}_clr wo — When SWGPIO @ Set/Clear Mode Set this bit will clear GPIO output value to 0,when set/clr at the same time, only set take effect
  [25] reg_gpio_{i}_set wo — When SWGPIO @ Set/Clear Mode Set this bit will set GPIO output value to 1,when set/clr at the same time, only set take effect
  [24] reg_gpio_{i}_o — When SWGPIO @ Output Value Mode 00 : GPIO Value changes according to this value 01 : GPIO Value Set by this register and clr by clr_reg
  [22] reg_gpio_{i}_int_mask — mask interrupt (1)
  [21] gpio_{i}_int_stat ro — interrupt status
  [20] reg_gpio_{i}_int_clr — clear interrupt
  [19:16] reg_gpio_{i}_int_mode_set — 0000 : sync falling edge trigger 0001 : sync rising edge trigger 0010 : sync low level trigger 0011 : sync high level trigger 01xx : sync rising & falling edge trigger 1000 : async falling edge trigger 1001 : async rising edge trigger 1010 : async low level trigger 1011 : async high level trigger
  [12:8] reg_gpio_{i}_func_sel — GPIO Function Select (Default : CCI)
  [6] reg_gpio_{i}_oe — Register Controlled GPIO Output Enable (Used when GPIO Function select to Register Control GPIO)
  [5] reg_gpio_{i}_pd — GPIO Pull Down Control
  [4] reg_gpio_{i}_pu — GPIO Pull Up Control
  [3:2] reg_gpio_{i}_drv — GPIO Driving Control
  [1] reg_gpio_{i}_smt — GPIO SMT Control
  [0] reg_gpio_{i}_ie — GPIO Input Enable
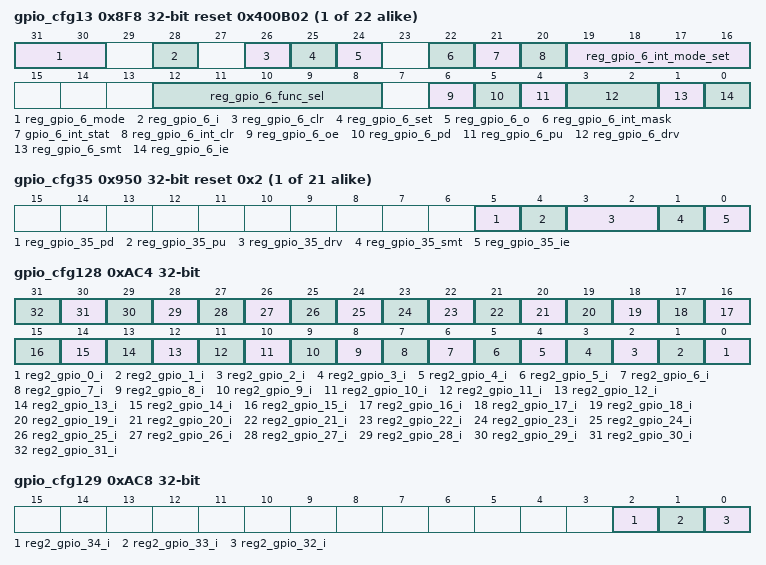
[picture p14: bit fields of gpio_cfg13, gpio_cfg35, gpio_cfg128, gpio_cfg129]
{0x8C4+4i} gpio_cfg{i} reset 0x400B02 (reset mask 0xC75F1F7F) (i=13..34)
  fields as gpio_cfg6
{0x8C4+4i} gpio_cfg{i} reset 0x2 (i=35..55)
  [5] reg_gpio_{i}_pd — GPIO Pull Down Control
  [4] reg_gpio_{i}_pu — GPIO Pull Up Control
  [3:2] reg_gpio_{i}_drv — GPIO Driving Control
  [1] reg_gpio_{i}_smt — GPIO SMT Control
  [0] reg_gpio_{i}_ie — GPIO Input Enable
{0x8C4+4i} gpio_cfg{i} reset not defined (i=56..63)
0xAC4 gpio_cfg128 reset not defined
  [n] reg2_gpio_{n}_i ro (n=0..31) — Register Controlled GPIO Input value
0xAC8 gpio_cfg129 reset not defined
  [2] reg2_gpio_34_i ro — Register Controlled GPIO Input value
  [1] reg2_gpio_33_i ro — Register Controlled GPIO Input value
  [0] reg2_gpio_32_i ro — Register Controlled GPIO Input value
0xAE4 gpio_cfg136
  [n] reg2_gpio_{n}_o (n=0..31) — Register Controlled GPIO Output Value
0xAE8 gpio_cfg137
  [2] reg2_gpio_34_o — Register Controlled GPIO Output Value
  [1] reg2_gpio_33_o — Register Controlled GPIO Output Value
  [0] reg2_gpio_32_o — Register Controlled GPIO Output Value
0xAEC gpio_cfg138
  [n] reg2_gpio_{n}_set wo (n=0..31) — When SWGPIO @ Set/Clear Mode Set this bit will set GPIO output value to 1,when set/clr at the same time, only set take effect
0xAF0 gpio_cfg139
  [2] reg2_gpio_34_set wo — When SWGPIO @ Set/Clear Mode Set this bit will set GPIO output value to 1,when set/clr at the same time, only set take effect
  [1] reg2_gpio_33_set wo — When SWGPIO @ Set/Clear Mode Set this bit will set GPIO output value to 1,when set/clr at the same time, only set take effect
  [0] reg2_gpio_32_set wo — When SWGPIO @ Set/Clear Mode Set this bit will set GPIO output value to 1,when set/clr at the same time, only set take effect
0xAF4 gpio_cfg140
  [n] reg2_gpio_{n}_clr wo (n=0..31) — When SWGPIO @ Set/Clear Mode Set this bit will clear GPIO output value to 0,when set/clr at the same time, only set take effect
0xAF8 gpio_cfg141
  [2] reg2_gpio_34_clr wo — When SWGPIO @ Set/Clear Mode Set this bit will clear GPIO output value to 0,when set/clr at the same time, only set take effect
  [1] reg2_gpio_33_clr wo — When SWGPIO @ Set/Clear Mode Set this bit will clear GPIO output value to 0,when set/clr at the same time, only set take effect
  [0] reg2_gpio_32_clr wo — When SWGPIO @ Set/Clear Mode Set this bit will clear GPIO output value to 0,when set/clr at the same time, only set take effect
0xAFC gpio_cfg142 reset 0xC8C8C800
  [31:24] cr_code1_high_time — Used to generate Code 1 Duty Cycle Waveform (in units of xclk (XTAL or RC32M) clock cycle) waveform keep high during cr_code1_high_time waveform keep low during cr_code1_low_time (cr_code_total_time - cr_code1_high_time )
  [23:16] cr_code0_high_time — Used to generate Code 0 Duty Cycle Waveform (in units of xclk (XTAL or RC32M) clock cycle) waveform keep high during cr_code0_high_time waveform keep low during cr_code0_low_time (cr_code_total_time - cr_code0_high_time)
  [15:7] cr_code_total_time — Used to define Code0/Code1 total waveform time
  [2] cr_invert_code1_high — 1: cr_code1_high_time -> cr_code1_low_time
  [1] cr_invert_code0_high — 1: cr_code0_high_time -> cr_code0_low_time
  [0] cr_gpio_tx_en — Enable GPIO DMA OUT/GPIO DMA Latch
0xB00 gpio_cfg143 reset 0xE3800000 (reset mask 0xE3FF008F)
  [31] cr_gpio_tx_fer_en — Interrupt enable of gpio_tx_fer_int (GPIO DMA FIFO Underflow or Overflow)
  [30] cr_gpio_tx_fifo_en — Interrupt enable of gpio_tx_fifo_int
  [29] cr_gpio_tx_end_en — Interrupt enable of gpio_tx_end_int
  [28] r_gpio_tx_fer_int ro — GPIO TX FIFO error interrupt, auto-cleared when FIFO overflow/underflow error flag is cleared
  [27] r_gpio_tx_fifo_int ro — GPIO TX FIFO ready (tx_fifo_cnt > tx_fifo_th) interrupt, auto-cleared when data is pushed
  [26] r_gpio_tx_end_int ro — GPIO TX END Interrupt (GPIO DMA FIFO Empty)
  [25] cr_gpio_tx_fer_mask — Interrupt mask of gpio_tx_fer_int
  [24] cr_gpio_tx_fifo_mask — Interrupt mask of gpio_tx_fifo_int
  [23] cr_gpio_tx_end_mask — Interrupt mask of gpio_tx_end_int
  [22:16] cr_gpio_tx_fifo_th — TX FIFO threshold, dma_tx_req will not be asserted if tx_fifo_cnt is less than this value
  [15:8] gpio_tx_fifo_cnt ro — TX FIFO available count
  [7] cr_gpio_dma_park_value — 1: park at high level when TX FIFO empty 0: park at low level when TX FIFO empty
  [5] gpio_tx_fifo_underflow ro — Underflow flag of TX FIFO, can be cleared by tx_fifo_clr
  [4] gpio_tx_fifo_overflow ro — Overflow flag of TX FIFO, can be cleared by tx_fifo_clr
  [3] gpio_tx_end_clr wo — Interrupt clear of gpio_tx_end_int
  [2] gpio_tx_fifo_clr wo — Clear signal of TX FIFO
  [1] cr_gpio_dma_out_sel_latch — 1 : select latch format (8bit set/8bit clr) , 0 : select 16bit output value
  [0] cr_gpio_dma_tx_en — Enable signal of dma_tx_req/ack interface
0xB04 gpio_cfg144
  [15:0] gpio_tx_data_to_fifo wo
0xB80 XTAL_DEG_32K reset 0x8000000
  [31] xtal_cnt_32k_sw_trig_ps wo — write one to set xtal_cnt_32k_process (0x4000E050[29])
  [28] clr_xtal_cnt_32k_done wo — write one to clear xtal_cnt_32k_done (0x4000E050[30])
  [27] xtal_cnt_32k_cgen
  [15] rc32k_deg_start_ps wo
  [14] rc32k_deg_end_ps wo
  [13] reg_rc32k_deg_en
  [9:8] top_misc_xtal_sel
  [7:0] xtal_deg_cnt_limit
0xB90 NEW_RTC_TIME_L reset not defined
  [31:0] rtc_timer_latch_l ro — RTC time latched value bit 31:0
0xB94 NEW_RTC_TIME_H reset not defined
  [31:0] rtc_timer_latch_h ro — RTC time latched value bit 63:32
0xB98 NEW_RTC_TIME_EN reset 0x1000000
  [24] reg_rtc_timer_latch_en — Enable RTC Timer Latch, need to wait about 15us for 1st timer read, and no need to wait for next read
